VERSION "1.10"

NS_ :

BS_:

BU_: EPS ESP BMS BCM
VAL_TABLE_ VtTestSig -2 "Description for the value '0x7'" -1 "Udef" 6 "Udef" 5 "Udef" 4 "Udef" 3 "Error" 2 "Ok" 1 "State one" 0 "State 1" ;

BO_ 273 NO_SIGS_MSG: 8 BCM

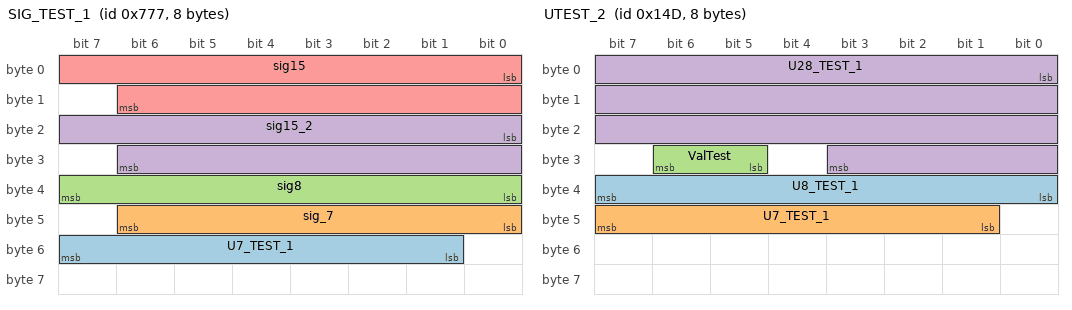
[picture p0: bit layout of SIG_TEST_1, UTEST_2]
BO_ 1911 SIG_TEST_1: 8 EPS
 SG_ U7_TEST_1 : 55|7@0+ (1,-255) [-255|-128] ""  BCM
 SG_ sig_7 : 40|7@1- (1.2,0) [-76.8|75.6] ""  BCM
 SG_ sig8 : 32|8@1- (5,0) [-640|635] ""  BCM
 SG_ sig15_2 : 16|15@1- (1.9,-2500) [-33629.6|28627.7] ""  BCM
 SG_ sig15 : 0|15@1- (3,-1024) [-50176|48125] ""  BCM

BO_ 2684354550 EMPTY_EXT_ID: 8 BCM
 SG_ CS : 13|6@0+ (1,0) [0|255] ""  BCM,ESP,BMS
 SG_ ValTest : 7|2@0+ (1,0) [0|0] "c"  BCM,ESP,BMS

BO_ 555 UTEST_3: 8 BCM
 SG_ TestValTableID : 32|3@1+ (1,0) [0|7] ""  BMS
 SG_ U32_TEST_1 : 0|32@1+ (1,0) [0|4294967295] ""  BMS

BO_ 333 UTEST_2: 8 BCM
 SG_ U8_TEST_1 : 39|8@0+ (1,0) [0|255] ""  BMS
 SG_ U7_TEST_1 : 47|7@0+ (1,-255) [-255|-128] ""  BMS
 SG_ ValTest : 30|2@0+ (1,0) [0|3] "c"  ESP,BMS
 SG_ U28_TEST_1 : 0|28@1+ (1,0) [0|4294967295] ""  ESP,BMS

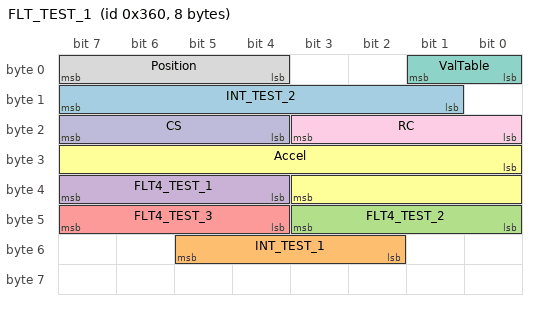
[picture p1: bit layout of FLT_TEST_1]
BO_ 864 FLT_TEST_1: 8 BMS
 SG_ INT_TEST_2 : 15|7@0- (5,0) [-320|315] ""  BCM
 SG_ INT_TEST_1 : 53|4@0+ (9,-11) [-11|124] ""  BCM
 SG_ FLT4_TEST_2 : 43|4@0+ (2.01,-5) [-5|25.15] ""  BCM
 SG_ FLT4_TEST_1 : 39|4@0+ (2.01,-0.01) [-0.01|30.14] ""  BCM
 SG_ FLT4_TEST_3 : 47|4@0+ (2,-10.1) [-10.1|19.9] ""  BCM
 SG_ Accel : 24|12@1+ (0.1,-100) [-100|309.5] "m/s"  BCM
 SG_ ValTable : 1|2@0+ (1,0) [0|3] "e"  BCM
 SG_ Position : 7|4@0+ (1,0) [0|15] ""  BCM
 SG_ RC : 16|4@1+ (1,0) [0|15] ""  BCM
 SG_ CS : 20|4@1+ (1,0) [0|15] ""  BCM

BO_ 352 EMPTY_0: 8 BCM
 SG_ CS : 38|6@0+ (1,0) [0|63] ""  BMS
 SG_ RC : 47|4@1+ (1,0) [0|15] ""  BMS

BO_TX_BU_ 352 : BMS,ESP,BCM;

CM_ BU_ BMS "Selector ECU info block
";
CM_ BU_ BCM "ESP ECU information";
CM_ SG_ 2684354550 CS "<Checksum:kXor8:1> test pattern";
CM_ SG_ 2684354550 ValTest "This is test signal for Value Table



";
CM_ SG_ 333 ValTest "This is test signal for Value Table



";
CM_ SG_ 864 Accel "Test floating point value.";
CM_ SG_ 864 ValTable "This is just comment.
Next line.";
CM_ SG_ 864 RC "<RollingCounter>";
CM_ SG_ 864 CS "<Checksum:kXor4:1>";
CM_ SG_ 352 CS "<Checksum:kXor8:1> test pattern";
CM_ SG_ 352 RC "<RollingCounter>";
BA_DEF_ SG_  "GenSigSendType" ENUM  "Cyclic","OnWrite","OnWriteWithRepetition","OnChange","OnChangeWithRepetition","IfActive","IfActiveWithRepetition","NoSigSendType";
BA_DEF_ BO_  "GenMsgSendType " ENUM  "Cyclic","not_used","not_used","not_used","not_used","Cyclic","not_used","IfActive","NoMsgSendType";
BA_DEF_  "DBName" STRING ;
BA_DEF_ BO_  "GenMsgCycleTime" INT 2 50000;
BA_DEF_ BO_  "GenMsgDelayTime" INT 1 1000;
BA_DEF_ BO_  "GenMsgNrOfRepetitions" INT 1 999999;
BA_DEF_ BO_  "GenMsgSendType" ENUM  "cyclic","spontaneous","cyclicIfActive","spontaneousWithDelay","cyclicAndSpontaneous","cyclicAndSpontaneousWithDelay","spontaneousWithRepetition","cyclicIfActiveAndSpontaneousWD";
BA_DEF_ SG_  "GenSigStartValue" FLOAT 0 100000000000;
BA_DEF_DEF_  "GenSigSendType" "Cyclic";
BA_DEF_DEF_  "GenMsgSendType " "NoMsgSendType";
BA_DEF_DEF_  "DBName" "";
BA_DEF_DEF_  "GenMsgCycleTime" 100;
BA_DEF_DEF_  "GenMsgDelayTime" 1;
BA_DEF_DEF_  "GenMsgNrOfRepetitions" 1;
BA_DEF_DEF_  "GenMsgSendType" "spontaneous";
BA_DEF_DEF_  "GenSigStartValue" 0;
BA_ "DBName" "ceedselector";
BA_ "GenMsgSendType" BO_ 2684354550 0;
BA_ "GenMsgCycleTime" BO_ 864 101;
BA_ "GenMsgSendType" BO_ 864 0;
BA_ "GenMsgCycleTime" BO_ 352 101;
BA_ "GenMsgSendType" BO_ 352 0;
BA_ "GenSigStartValue" SG_ 1911 sig15_2 1315.78947368421;
BA_ "GenSigStartValue" SG_ 1911 sig15 341.333333333333;
BA_ "GenSigStartValue" SG_ 864 INT_TEST_2 0.6;
BA_ "GenSigStartValue" SG_ 864 FLT4_TEST_3 5.05;
BA_ "GenSigStartValue" SG_ 864 Accel 1000;
VAL_ 2684354550 ValTest 3 "Unsupported" 2 "Fail" 1 "OK" 0 "Undefined" ;
VAL_ 555 TestValTableID -2 "Description for the value '0x7'" -1 "Udef" 6 "Udef" 5 "Udef" 4 "Udef" 3 "Error" 2 "Ok" 1 "State one" 0 "State 1" ;
VAL_ 333 ValTest 3 "Unsupported" 2 "Fail" 1 "OK" 0 "Undefined" ;
VAL_ 864 ValTable 3 "Unsupported" 2 "Fail" 1 "OK" 0 "Undefined" ;
